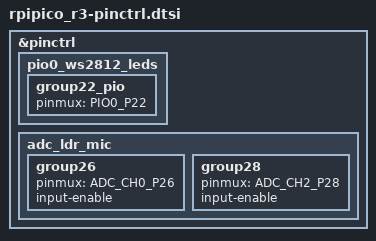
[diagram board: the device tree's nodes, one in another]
/*
 * SPDX-FileCopyrightText: Copyright (c) 2026 TiaC Systems
 * SPDX-License-Identifier: Apache-2.0
 */

&pinctrl {
	pio0_ws2812_leds: pio0_ws2812_leds {
		group22_pio {
			pinmux = <PIO0_P22>;	/* GP22: PIO0 */
		};
	};

	adc_ldr_mic: adc_ldr_mic {
		group26 {
			pinmux = <ADC_CH0_P26>;	/* GP26: ADC0 (LDR) */
			input-enable;
		};
		group28 {
			pinmux = <ADC_CH2_P28>;	/* GP28: ADC2 (MIC) */
			input-enable;
		};
	};
};
